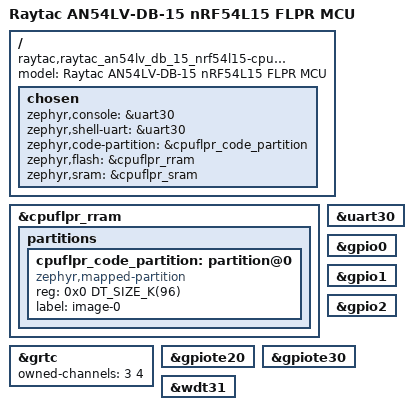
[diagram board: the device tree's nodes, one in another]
/*
 * Copyright (c) 2024 Nordic Semiconductor ASA
 * Copyright (c) 2025 Raytac Corporation.
 *
 * SPDX-License-Identifier: Apache-2.0
 */

/dts-v1/;
#include <nordic/nrf54l15_cpuflpr.dtsi>
#include "raytac_an54lv_db_15_common.dtsi"

/ {
	compatible = "raytac,raytac_an54lv_db_15_nrf54l15-cpuflpr";
	model = "Raytac AN54LV-DB-15 nRF54L15 FLPR MCU";

	chosen {
		zephyr,console = &uart30;
		zephyr,shell-uart = &uart30;
		zephyr,code-partition = &cpuflpr_code_partition;
		zephyr,flash = &cpuflpr_rram;
		zephyr,sram = &cpuflpr_sram;
	};
};

&cpuflpr_rram {
	partitions {
		ranges;
		#address-cells = <1>;
		#size-cells = <1>;

		cpuflpr_code_partition: partition@0 {
			compatible = "zephyr,mapped-partition";
			reg = <0x0 DT_SIZE_K(96)>;
			label = "image-0";
		};
	};
};

&grtc {
	owned-channels = <3 4>;
	status = "okay";
};

&uart30 {
	status = "okay";
};

&gpio0 {
	status = "okay";
};

&gpio1 {
	status = "okay";
};

&gpio2 {
	status = "okay";
};

&gpiote20 {
	status = "okay";
};

&gpiote30 {
	status = "okay";
};

&wdt31 {
	status = "okay";
};
